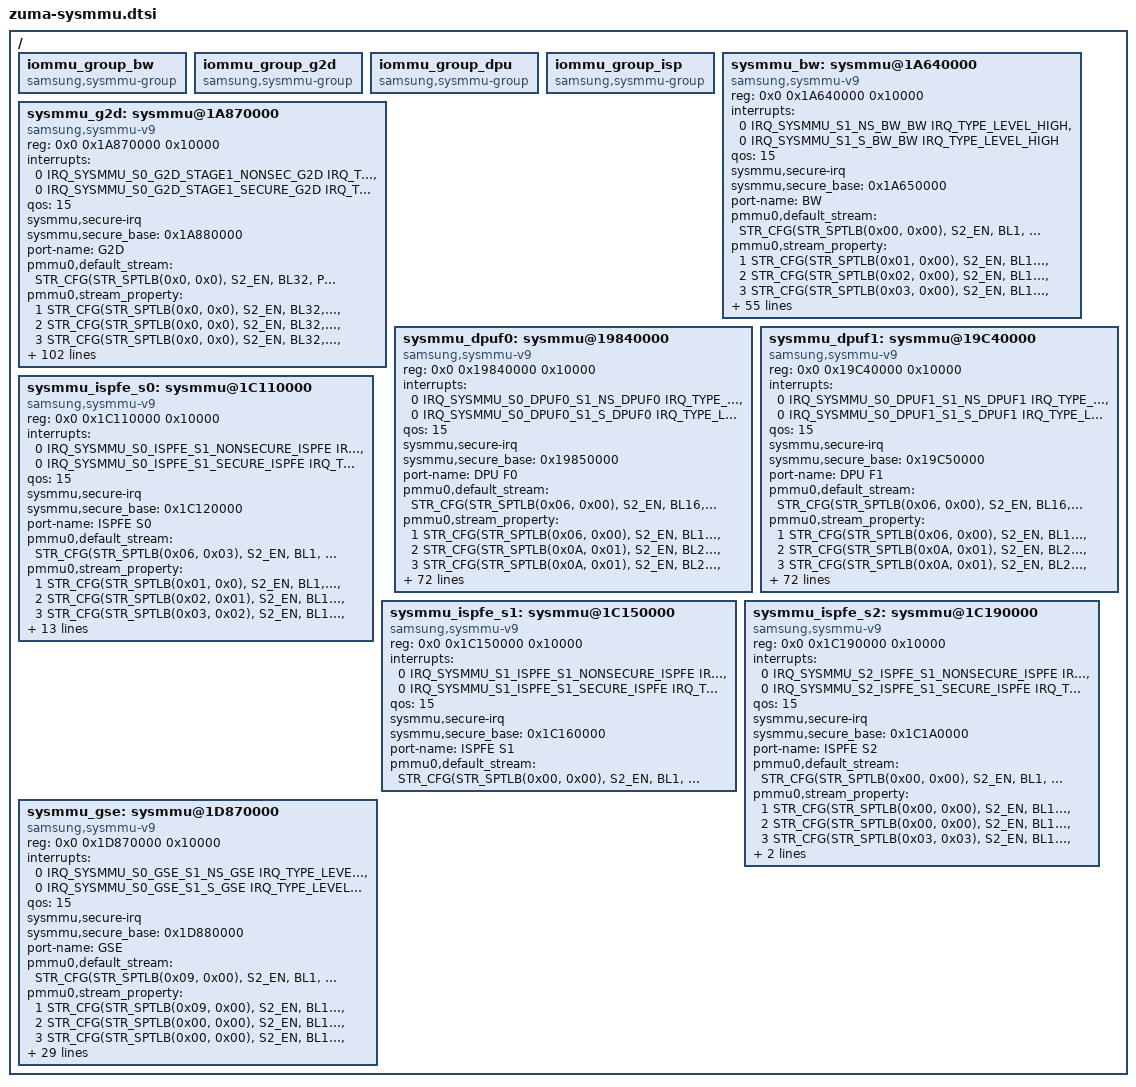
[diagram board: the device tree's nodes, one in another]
// SPDX-License-Identifier: GPL-2.0-only
/*
 * Copyright (c) 2021 Samsung Electronics Co., Ltd.
 *
 */

#include <dt-bindings/interrupt-controller/arm-gic.h>
#include <dt-bindings/interrupt-controller/zuma.h>
#include <dt-bindings/soc/samsung_sysmmu_v9.h>

/ {
	iommu_group_bw: iommu_group_bw {
		compatible = "samsung,sysmmu-group";
	};

	iommu_group_g2d: iommu_group_g2d {
		compatible = "samsung,sysmmu-group";
	};

	iommu_group_dpu: iommu_group_dpu {
		compatible = "samsung,sysmmu-group";
	};

	iommu_group_isp: iommu_group_isp {
		compatible = "samsung,sysmmu-group";
	};

	sysmmu_bw: sysmmu@1A640000 {
		compatible = "samsung,sysmmu-v9";
		reg = <0x0 0x1A640000 0x10000>;

		interrupts = <0 IRQ_SYSMMU_S1_NS_BW_BW IRQ_TYPE_LEVEL_HIGH>,
			     <0 IRQ_SYSMMU_S1_S_BW_BW IRQ_TYPE_LEVEL_HIGH>;

		qos = <15>;

		sysmmu,secure-irq;
		sysmmu,secure_base = <0x1A650000>;
/*		power-domains = <&pd_bw>;
 */
		port-name = "BW";
		#iommu-cells = <0>;
		pmmu0,default_stream = <STR_CFG(STR_SPTLB(0x00, 0x00), S2_EN, BL1, PREF_PRED, STLB_PREF, PTLB_PREF) >;
		pmmu0,stream_property =
			<1 STR_CFG(STR_SPTLB(0x01, 0x00), S2_EN, BL1, PREF_PRED, STLB_PREF, PTLB_PREF) DIR_READ STR_ID(0x02) STR_MASK(0x1F)>,
			<2 STR_CFG(STR_SPTLB(0x02, 0x00), S2_EN, BL1, PREF_PRED, STLB_PREF, PTLB_PREF) DIR_READ STR_ID(0x03) STR_MASK(0x1F)>,
			<3 STR_CFG(STR_SPTLB(0x03, 0x00), S2_EN, BL1, PREF_PRED, STLB_PREF, PTLB_PREF) DIR_READ STR_ID(0x04) STR_MASK(0x1F)>,
			<4 STR_CFG(STR_SPTLB(0x04, 0x00), S2_EN, BL1, PREF_PRED, STLB_PREF, PTLB_PREF) DIR_READ STR_ID(0x05) STR_MASK(0x1F)>,
			<5 STR_CFG(STR_SPTLB(0x00, 0x00), S2_EN, BL1, PREF_PRED, STLB_PREF, PTLB_PREF) DIR_READ STR_ID(0x06) STR_MASK(0x1F)>,
			<6 STR_CFG(STR_SPTLB(0x00, 0x00), S2_EN, BL1, PREF_PRED, STLB_PREF, PTLB_PREF) DIR_READ STR_ID(0x07) STR_MASK(0x1F)>,
			<7 STR_CFG(STR_SPTLB(0x00, 0x00), S2_EN, BL1, PREF_PRED, STLB_PREF, PTLB_PREF) DIR_READ STR_ID(0x08) STR_MASK(0x1F)>,
			<8 STR_CFG(STR_SPTLB(0x00, 0x00), S2_EN, BL1, PREF_PRED, STLB_PREF, PTLB_PREF) DIR_READ STR_ID(0x09) STR_MASK(0x1F)>,
			<9 STR_CFG(STR_SPTLB(0x00, 0x00), S2_EN, BL1, PREF_PRED, STLB_PREF, PTLB_PREF) DIR_READ STR_ID(0x0A) STR_MASK(0x1F)>,
			<10 STR_CFG(STR_SPTLB(0x00, 0x00), S2_EN, BL1, PREF_PRED, STLB_PREF, PTLB_PREF) DIR_READ STR_ID(0x0B) STR_MASK(0x1F)>,
			<11 STR_CFG(STR_SPTLB(0x00, 0x00), S2_EN, BL1, PREF_PRED, STLB_PREF, PTLB_PREF) DIR_READ STR_ID(0x0C) STR_MASK(0x1F)>,
			<12 STR_CFG(STR_SPTLB(0x00, 0x00), S2_EN, BL1, PREF_PRED, STLB_PREF, PTLB_PREF) DIR_READ STR_ID(0x0D) STR_MASK(0x1F)>,
			<13 STR_CFG(STR_SPTLB(0x00, 0x00), S2_EN, BL1, PREF_PRED, STLB_PREF, PTLB_PREF) DIR_READ STR_ID(0x0E) STR_MASK(0x1F)>,
			<14 STR_CFG(STR_SPTLB(0x00, 0x00), S2_EN, BL1, PREF_PRED, STLB_PREF, PTLB_PREF) DIR_READ STR_ID(0x0F) STR_MASK(0x1F)>,
			<15 STR_CFG(STR_SPTLB(0x00, 0x00), S2_EN, BL1, PREF_PRED, STLB_PREF, PTLB_PREF) DIR_READ STR_ID(0x10) STR_MASK(0x1F)>,
			<16 STR_CFG(STR_SPTLB(0x00, 0x00), S2_EN, BL1, PREF_PRED, STLB_PREF, PTLB_PREF) DIR_READ STR_ID(0x11) STR_MASK(0x1F)>,
			<17 STR_CFG(STR_SPTLB(0x00, 0x00), S2_EN, BL1, PREF_PRED, STLB_NONE, PTLB_NONE) DIR_READ STR_ID(0x12) STR_MASK(0x1F)>,
			<18 STR_CFG(STR_SPTLB(0x00, 0x00), S2_EN, BL1, PREF_PRED, STLB_PREF, PTLB_PREF) DIR_READ STR_ID(0x13) STR_MASK(0x1F)>,
			<19 STR_CFG(STR_SPTLB(0x00, 0x00), S2_EN, BL1, PREF_PRED, STLB_PREF, PTLB_PREF) DIR_READ STR_ID(0x14) STR_MASK(0x1F)>,
			<20 STR_CFG(STR_SPTLB(0x00, 0x00), S2_EN, BL1, PREF_PRED, STLB_PREF, PTLB_PREF) DIR_READ STR_ID(0x15) STR_MASK(0x1F)>,
			<21 STR_CFG(STR_SPTLB(0x00, 0x00), S2_EN, BL1, PREF_PRED, STLB_PREF, PTLB_PREF) DIR_READ STR_ID(0x16) STR_MASK(0x1F)>,
			<22 STR_CFG(STR_SPTLB(0x00, 0x00), S2_EN, BL1, PREF_PRED, STLB_NONE, PTLB_NONE) DIR_READ STR_ID(0x17) STR_MASK(0x1F)>,
			<23 STR_CFG(STR_SPTLB(0x00, 0x00), S2_EN, BL1, PREF_PRED, STLB_PREF, PTLB_PREF) DIR_READ STR_ID(0x18) STR_MASK(0x1F)>,
			<24 STR_CFG(STR_SPTLB(0x00, 0x00), S2_EN, BL1, PREF_PRED, STLB_PREF, PTLB_PREF) DIR_READ STR_ID(0x19) STR_MASK(0x1F)>,
			<25 STR_CFG(STR_SPTLB(0x00, 0x00), S2_EN, BL1, PREF_PRED, STLB_PREF, PTLB_PREF) DIR_READ STR_ID(0x1A) STR_MASK(0x1F)>,
			<26 STR_CFG(STR_SPTLB(0x00, 0x00), S2_EN, BL1, PREF_PRED, STLB_PREF, PTLB_PREF) DIR_READ STR_ID(0x1B) STR_MASK(0x1F)>,
			<27 STR_CFG(STR_SPTLB(0x00, 0x00), S2_EN, BL1, PREF_PRED, STLB_NONE, PTLB_NONE) DIR_READ STR_ID(0x1C) STR_MASK(0x1F)>,
			<28 STR_CFG(STR_SPTLB(0x00, 0x00), S2_EN, BL1, PREF_PRED, STLB_PREF, PTLB_PREF) DIR_READ STR_ID(0x1D) STR_MASK(0x1F)>,
			<29 STR_CFG(STR_SPTLB(0x00, 0x00), S2_EN, BL1, PREF_PRED, STLB_PREF, PTLB_PREF) DIR_READ STR_ID(0x1E) STR_MASK(0x1F)>,
			<30 STR_CFG(STR_SPTLB(0x00, 0x00), S2_EN, BL1, PREF_PRED, STLB_PREF, PTLB_PREF) DIR_READ STR_ID(0x1F) STR_MASK(0x1F)>,
			<31 STR_CFG(STR_SPTLB(0x00, 0x00), S2_EN, BL1, PREF_PRED, STLB_PREF, PTLB_PREF) DIR_WRITE STR_ID(0x01) STR_MASK(0x3F)>,
			<32 STR_CFG(STR_SPTLB(0x00, 0x00), S2_EN, BL1, PREF_PRED, STLB_NONE, PTLB_NONE) DIR_WRITE STR_ID(0x02) STR_MASK(0x3F)>,
			<33 STR_CFG(STR_SPTLB(0x00, 0x00), S2_EN, BL1, PREF_PRED, STLB_PREF, PTLB_PREF) DIR_WRITE STR_ID(0x03) STR_MASK(0x3F)>,
			<34 STR_CFG(STR_SPTLB(0x00, 0x00), S2_EN, BL1, PREF_PRED, STLB_PREF, PTLB_PREF) DIR_WRITE STR_ID(0x04) STR_MASK(0x3F)>,
			<35 STR_CFG(STR_SPTLB(0x00, 0x00), S2_EN, BL1, PREF_PRED, STLB_PREF, PTLB_PREF) DIR_WRITE STR_ID(0x05) STR_MASK(0x3F)>,
			<36 STR_CFG(STR_SPTLB(0x00, 0x00), S2_EN, BL1, PREF_PRED, STLB_PREF, PTLB_PREF) DIR_WRITE STR_ID(0x06) STR_MASK(0x3F)>,
			<37 STR_CFG(STR_SPTLB(0x00, 0x00), S2_EN, BL1, PREF_PRED, STLB_PREF, PTLB_PREF) DIR_WRITE STR_ID(0x07) STR_MASK(0x3F)>,
			<38 STR_CFG(STR_SPTLB(0x00, 0x00), S2_EN, BL1, PREF_PRED, STLB_PREF, PTLB_PREF) DIR_WRITE STR_ID(0x08) STR_MASK(0x3F)>,
			<39 STR_CFG(STR_SPTLB(0x00, 0x00), S2_EN, BL1, PREF_PRED, STLB_PREF, PTLB_PREF) DIR_WRITE STR_ID(0x09) STR_MASK(0x3F)>,
			<40 STR_CFG(STR_SPTLB(0x00, 0x00), S2_EN, BL1, PREF_PRED, STLB_PREF, PTLB_PREF) DIR_WRITE STR_ID(0x0A) STR_MASK(0x3F)>,
			<41 STR_CFG(STR_SPTLB(0x00, 0x00), S2_EN, BL1, PREF_PRED, STLB_PREF, PTLB_PREF) DIR_WRITE STR_ID(0x0B) STR_MASK(0x3F)>,
			<42 STR_CFG(STR_SPTLB(0x00, 0x00), S2_EN, BL1, PREF_PRED, STLB_PREF, PTLB_PREF) DIR_WRITE STR_ID(0x0C) STR_MASK(0x3F)>,
			<43 STR_CFG(STR_SPTLB(0x00, 0x00), S2_EN, BL1, PREF_PRED, STLB_PREF, PTLB_PREF) DIR_WRITE STR_ID(0x0D) STR_MASK(0x3F)>,
			<44 STR_CFG(STR_SPTLB(0x00, 0x00), S2_EN, BL1, PREF_PRED, STLB_PREF, PTLB_PREF) DIR_WRITE STR_ID(0x0E) STR_MASK(0x3F)>,
			<45 STR_CFG(STR_SPTLB(0x00, 0x00), S2_EN, BL1, PREF_PRED, STLB_PREF, PTLB_PREF) DIR_WRITE STR_ID(0x0F) STR_MASK(0x3F)>,
			<46 STR_CFG(STR_SPTLB(0x00, 0x00), S2_EN, BL1, PREF_PRED, STLB_PREF, PTLB_PREF) DIR_WRITE STR_ID(0x10) STR_MASK(0x3F)>,
			<47 STR_CFG(STR_SPTLB(0x00, 0x00), S2_EN, BL1, PREF_PRED, STLB_PREF, PTLB_PREF) DIR_WRITE STR_ID(0x11) STR_MASK(0x3F)>,
			<48 STR_CFG(STR_SPTLB(0x00, 0x00), S2_EN, BL1, PREF_PRED, STLB_PREF, PTLB_PREF) DIR_WRITE STR_ID(0x12) STR_MASK(0x3F)>,
			<49 STR_CFG(STR_SPTLB(0x00, 0x00), S2_EN, BL1, PREF_PRED, STLB_NONE, PTLB_NONE) DIR_WRITE STR_ID(0x13) STR_MASK(0x3F)>,
			<50 STR_CFG(STR_SPTLB(0x00, 0x00), S2_EN, BL1, PREF_PRED, STLB_NONE, PTLB_NONE) DIR_WRITE STR_ID(0x14) STR_MASK(0x3F)>,
			<51 STR_CFG(STR_SPTLB(0x00, 0x00), S2_EN, BL8, PREF_PRED, STLB_PREF, PTLB_PREF) DIR_WRITE STR_ID(0x15) STR_MASK(0x3F)>,
			<52 STR_CFG(STR_SPTLB(0x00, 0x00), S2_EN, BL1, PREF_PRED, STLB_NONE, PTLB_NONE) DIR_WRITE STR_ID(0x16) STR_MASK(0x3F)>,
			<53 STR_CFG(STR_SPTLB(0x00, 0x00), S2_EN, BL8, PREF_PRED, STLB_PREF, PTLB_PREF) DIR_WRITE STR_ID(0x17) STR_MASK(0x3F)>,
			<54 STR_CFG(STR_SPTLB(0x00, 0x00), S2_EN, BL1, PREF_PRED, STLB_NONE, PTLB_NONE) DIR_WRITE STR_ID(0x18) STR_MASK(0x3F)>,
			<55 STR_CFG(STR_SPTLB(0x00, 0x00), S2_EN, BL8, PREF_PRED, STLB_PREF, PTLB_PREF) DIR_WRITE STR_ID(0x19) STR_MASK(0x3F)>,
			<56 STR_CFG(STR_SPTLB(0x00, 0x00), S2_EN, BL1, PREF_PRED, STLB_NONE, PTLB_NONE) DIR_WRITE STR_ID(0x1A) STR_MASK(0x3F)>,
			<57 STR_CFG(STR_SPTLB(0x00, 0x00), S2_EN, BL8, PREF_PRED, STLB_PREF, PTLB_PREF) DIR_WRITE STR_ID(0x1B) STR_MASK(0x3F)>,
			<58 STR_CFG(STR_SPTLB(0x00, 0x00), S2_EN, BL1, PREF_PRED, STLB_NONE, PTLB_NONE) DIR_WRITE STR_ID(0x1C) STR_MASK(0x3F)>;
	};

	sysmmu_g2d: sysmmu@1A870000 {
		compatible = "samsung,sysmmu-v9";
		reg = <0x0 0x1A870000 0x10000>;

		interrupts = <0 IRQ_SYSMMU_S0_G2D_STAGE1_NONSEC_G2D IRQ_TYPE_LEVEL_HIGH>,
			     <0 IRQ_SYSMMU_S0_G2D_STAGE1_SECURE_G2D IRQ_TYPE_LEVEL_HIGH>;

		qos = <15>;

		sysmmu,secure-irq;
		sysmmu,secure_base = <0x1A880000>;
/*		power-domains = <&pd_g2d>;
 */
		port-name = "G2D";
		#iommu-cells = <0>;

		pmmu0,default_stream = <STR_CFG(STR_SPTLB(0x0, 0x0), S2_EN, BL32, PREF_PRED, STLB_NONE, PTLB_NONE)>;
		pmmu0,stream_property =
			<1 STR_CFG(STR_SPTLB(0x0, 0x0), S2_EN, BL32, PREF_PRED, STLB_NONE, PTLB_NONE) DIR_RW STR_ID(0x01) STR_MASK(0x7F)>,
			<2 STR_CFG(STR_SPTLB(0x0, 0x0), S2_EN, BL32, PREF_PRED, STLB_NONE, PTLB_NONE) DIR_RW STR_ID(0x02) STR_MASK(0x7F)>,
			<3 STR_CFG(STR_SPTLB(0x0, 0x0), S2_EN, BL32, PREF_PRED, STLB_NONE, PTLB_NONE) DIR_RW STR_ID(0x03) STR_MASK(0x7F)>,
			<4 STR_CFG(STR_SPTLB(0x0, 0x0), S2_EN, BL32, PREF_PRED, STLB_NONE, PTLB_NONE) DIR_RW STR_ID(0x04) STR_MASK(0x7F)>,
			<5 STR_CFG(STR_SPTLB(0x0, 0x0), S2_EN, BL32, PREF_PRED, STLB_NONE, PTLB_NONE) DIR_RW STR_ID(0x09) STR_MASK(0x7F)>,
			<6 STR_CFG(STR_SPTLB(0x0, 0x0), S2_EN, BL32, PREF_PRED, STLB_NONE, PTLB_NONE) DIR_RW STR_ID(0x0A) STR_MASK(0x7F)>,
			<7 STR_CFG(STR_SPTLB(0x0, 0x0), S2_EN, BL32, PREF_PRED, STLB_NONE, PTLB_NONE) DIR_RW STR_ID(0x0B) STR_MASK(0x7F)>,
			<8 STR_CFG(STR_SPTLB(0x0, 0x0), S2_EN, BL32, PREF_PRED, STLB_NONE, PTLB_NONE) DIR_RW STR_ID(0x0C) STR_MASK(0x7F)>,
			<9 STR_CFG(STR_SPTLB(0x0, 0x0), S2_EN, BL32, PREF_PRED, STLB_NONE, PTLB_NONE) DIR_RW STR_ID(0x11) STR_MASK(0x7F)>,
			<10 STR_CFG(STR_SPTLB(0x0, 0x0), S2_EN, BL32, PREF_PRED, STLB_NONE, PTLB_NONE) DIR_RW STR_ID(0x12) STR_MASK(0x7F)>,
			<11 STR_CFG(STR_SPTLB(0x0, 0x0), S2_EN, BL32, PREF_PRED, STLB_NONE, PTLB_NONE) DIR_RW STR_ID(0x13) STR_MASK(0x7F)>,
			<12 STR_CFG(STR_SPTLB(0x0, 0x0), S2_EN, BL32, PREF_PRED, STLB_NONE, PTLB_NONE) DIR_RW STR_ID(0x14) STR_MASK(0x7F)>,
			<13 STR_CFG(STR_SPTLB(0x0, 0x0), S2_EN, BL32, PREF_PRED, STLB_NONE, PTLB_NONE) DIR_RW STR_ID(0x21) STR_MASK(0x7F)>,
			<14 STR_CFG(STR_SPTLB(0x0, 0x0), S2_EN, BL32, PREF_PRED, STLB_NONE, PTLB_NONE) DIR_RW STR_ID(0x22) STR_MASK(0x7F)>,
			<15 STR_CFG(STR_SPTLB(0x0, 0x0), S2_EN, BL32, PREF_PRED, STLB_NONE, PTLB_NONE) DIR_RW STR_ID(0x23) STR_MASK(0x7F)>,
			<16 STR_CFG(STR_SPTLB(0x0, 0x0), S2_EN, BL32, PREF_PRED, STLB_NONE, PTLB_NONE) DIR_RW STR_ID(0x24) STR_MASK(0x7F)>,
			<17 STR_CFG(STR_SPTLB(0x0, 0x0), S2_EN, BL32, PREF_PRED, STLB_NONE, PTLB_NONE) DIR_RW STR_ID(0x29) STR_MASK(0x7F)>,
			<18 STR_CFG(STR_SPTLB(0x0, 0x0), S2_EN, BL32, PREF_PRED, STLB_NONE, PTLB_NONE) DIR_RW STR_ID(0x2A) STR_MASK(0x7F)>,
			<19 STR_CFG(STR_SPTLB(0x0, 0x0), S2_EN, BL32, PREF_PRED, STLB_NONE, PTLB_NONE) DIR_RW STR_ID(0x2B) STR_MASK(0x7F)>,
			<20 STR_CFG(STR_SPTLB(0x0, 0x0), S2_EN, BL32, PREF_PRED, STLB_NONE, PTLB_NONE) DIR_RW STR_ID(0x2C) STR_MASK(0x7F)>,
			<21 STR_CFG(STR_SPTLB(0x0, 0x0), S2_EN, BL32, PREF_PRED, STLB_NONE, PTLB_NONE) DIR_RW STR_ID(0x40) STR_MASK(0x7F)>,
			<22 STR_CFG(STR_SPTLB(0x0, 0x0), S2_EN, BL32, PREF_PRED, STLB_NONE, PTLB_NONE) DIR_RW STR_ID(0x41) STR_MASK(0x7F)>,
			<23 STR_CFG(STR_SPTLB(0x0, 0x0), S2_EN, BL32, PREF_PRED, STLB_NONE, PTLB_NONE) DIR_RW STR_ID(0x42) STR_MASK(0x7F)>,
			<24 STR_CFG(STR_SPTLB(0x0, 0x0), S2_EN, BL32, PREF_PRED, STLB_NONE, PTLB_NONE) DIR_RW STR_ID(0x43) STR_MASK(0x7F)>,
			<25 STR_CFG(STR_SPTLB(0x0, 0x0), S2_EN, BL32, PREF_PRED, STLB_NONE, PTLB_NONE) DIR_RW STR_ID(0x44) STR_MASK(0x7F)>,
			<26 STR_CFG(STR_SPTLB(0x0, 0x0), S2_EN, BL32, PREF_PRED, STLB_NONE, PTLB_NONE) DIR_RW STR_ID(0x49) STR_MASK(0x7F)>,
			<27 STR_CFG(STR_SPTLB(0x0, 0x0), S2_EN, BL32, PREF_PRED, STLB_NONE, PTLB_NONE) DIR_RW STR_ID(0x4A) STR_MASK(0x7F)>,
			<28 STR_CFG(STR_SPTLB(0x0, 0x0), S2_EN, BL32, PREF_PRED, STLB_NONE, PTLB_NONE) DIR_RW STR_ID(0x4B) STR_MASK(0x7F)>,
			<29 STR_CFG(STR_SPTLB(0x0, 0x0), S2_EN, BL32, PREF_PRED, STLB_NONE, PTLB_NONE) DIR_RW STR_ID(0x4C) STR_MASK(0x7F)>,
			<30 STR_CFG(STR_SPTLB(0x0, 0x0), S2_EN, BL32, PREF_PRED, STLB_NONE, PTLB_NONE) DIR_RW STR_ID(0x51) STR_MASK(0x7F)>,
			<31 STR_CFG(STR_SPTLB(0x0, 0x0), S2_EN, BL32, PREF_PRED, STLB_NONE, PTLB_NONE) DIR_RW STR_ID(0x52) STR_MASK(0x7F)>,
			<32 STR_CFG(STR_SPTLB(0x0, 0x0), S2_EN, BL32, PREF_PRED, STLB_NONE, PTLB_NONE) DIR_RW STR_ID(0x53) STR_MASK(0x7F)>,
			<33 STR_CFG(STR_SPTLB(0x0, 0x0), S2_EN, BL32, PREF_PRED, STLB_NONE, PTLB_NONE) DIR_RW STR_ID(0x54) STR_MASK(0x7F)>,
			<34 STR_CFG(STR_SPTLB(0x0, 0x0), S2_EN, BL32, PREF_PRED, STLB_NONE, PTLB_NONE) DIR_RW STR_ID(0x61) STR_MASK(0x7F)>,
			<35 STR_CFG(STR_SPTLB(0x0, 0x0), S2_EN, BL32, PREF_PRED, STLB_NONE, PTLB_NONE) DIR_RW STR_ID(0x62) STR_MASK(0x7F)>,
			<36 STR_CFG(STR_SPTLB(0x0, 0x0), S2_EN, BL32, PREF_PRED, STLB_NONE, PTLB_NONE) DIR_RW STR_ID(0x63) STR_MASK(0x7F)>,
			<37 STR_CFG(STR_SPTLB(0x0, 0x0), S2_EN, BL32, PREF_PRED, STLB_NONE, PTLB_NONE) DIR_RW STR_ID(0x64) STR_MASK(0x7F)>,
			<38 STR_CFG(STR_SPTLB(0x0, 0x0), S2_EN, BL32, PREF_PRED, STLB_NONE, PTLB_NONE) DIR_RW STR_ID(0x69) STR_MASK(0x7F)>,
			<39 STR_CFG(STR_SPTLB(0x0, 0x0), S2_EN, BL32, PREF_PRED, STLB_NONE, PTLB_NONE) DIR_RW STR_ID(0x6A) STR_MASK(0x7F)>,
			<40 STR_CFG(STR_SPTLB(0x0, 0x0), S2_EN, BL32, PREF_PRED, STLB_NONE, PTLB_NONE) DIR_RW STR_ID(0x6B) STR_MASK(0x7F)>,
			<41 STR_CFG(STR_SPTLB(0x0, 0x0), S2_EN, BL32, PREF_PRED, STLB_NONE, PTLB_NONE) DIR_RW STR_ID(0x6C) STR_MASK(0x7F)>,
			<42 STR_CFG(STR_SPTLB(0x0, 0x0), S2_EN, BL32, PREF_PRED, STLB_NONE, PTLB_NONE) DIR_RW STR_ID(0x00) STR_MASK(0x3F)>,
			<43 STR_CFG(STR_SPTLB(0x0, 0x0), S2_EN, BL32, PREF_PRED, STLB_NONE, PTLB_NONE) DIR_RW STR_ID(0x04) STR_MASK(0x3F)>,
			<44 STR_CFG(STR_SPTLB(0x0, 0x0), S2_EN, BL32, PREF_PRED, STLB_NONE, PTLB_NONE) DIR_RW STR_ID(0x08) STR_MASK(0x3F)>,
			<45 STR_CFG(STR_SPTLB(0x0, 0x0), S2_EN, BL32, PREF_PRED, STLB_NONE, PTLB_NONE) DIR_RW STR_ID(0x10) STR_MASK(0x3F)>,
			<46 STR_CFG(STR_SPTLB(0x0, 0x0), S2_EN, BL32, PREF_PRED, STLB_NONE, PTLB_NONE) DIR_RW STR_ID(0x14) STR_MASK(0x3F)>,
			<47 STR_CFG(STR_SPTLB(0x0, 0x0), S2_EN, BL32, PREF_PRED, STLB_NONE, PTLB_NONE) DIR_RW STR_ID(0x20) STR_MASK(0x3F)>,
			<48 STR_CFG(STR_SPTLB(0x0, 0x0), S2_EN, BL32, PREF_PRED, STLB_NONE, PTLB_NONE) DIR_RW STR_ID(0x24) STR_MASK(0x3F)>,
			<49 STR_CFG(STR_SPTLB(0x0, 0x0), S2_EN, BL32, PREF_PRED, STLB_NONE, PTLB_NONE) DIR_RW STR_ID(0x28) STR_MASK(0x3F)>,
			<50 STR_CFG(STR_SPTLB(0x0, 0x0), S2_EN, BL32, PREF_PRED, STLB_NONE, PTLB_NONE) DIR_RW STR_ID(0x30) STR_MASK(0x3F)>,
			<51 STR_CFG(STR_SPTLB(0x0, 0x0), S2_EN, BL32, PREF_PRED, STLB_NONE, PTLB_NONE) DIR_RW STR_ID(0x34) STR_MASK(0x3F)>;

		pmmu1,default_stream = <STR_CFG(STR_SPTLB(0x0, 0x0), S2_EN, BL32, PREF_PRED, STLB_NONE, PTLB_NONE)>;
		pmmu1,stream_property =
			<1 STR_CFG(STR_SPTLB(0x0, 0x0), S2_EN, BL32, PREF_PRED, STLB_NONE, PTLB_NONE) DIR_RW STR_ID(0x02) STR_MASK(0x7F)>,
			<2 STR_CFG(STR_SPTLB(0x0, 0x0), S2_EN, BL32, PREF_PRED, STLB_NONE, PTLB_NONE) DIR_RW STR_ID(0x03) STR_MASK(0x7F)>,
			<3 STR_CFG(STR_SPTLB(0x0, 0x0), S2_EN, BL32, PREF_PRED, STLB_NONE, PTLB_NONE) DIR_RW STR_ID(0x04) STR_MASK(0x7F)>,
			<4 STR_CFG(STR_SPTLB(0x0, 0x0), S2_EN, BL32, PREF_PRED, STLB_NONE, PTLB_NONE) DIR_RW STR_ID(0x09) STR_MASK(0x7F)>,
			<5 STR_CFG(STR_SPTLB(0x0, 0x0), S2_EN, BL32, PREF_PRED, STLB_NONE, PTLB_NONE) DIR_RW STR_ID(0x0A) STR_MASK(0x7F)>,
			<6 STR_CFG(STR_SPTLB(0x0, 0x0), S2_EN, BL32, PREF_PRED, STLB_NONE, PTLB_NONE) DIR_RW STR_ID(0x0B) STR_MASK(0x7F)>,
			<7 STR_CFG(STR_SPTLB(0x0, 0x0), S2_EN, BL32, PREF_PRED, STLB_NONE, PTLB_NONE) DIR_RW STR_ID(0x0C) STR_MASK(0x7F)>,
			<8 STR_CFG(STR_SPTLB(0x0, 0x0), S2_EN, BL32, PREF_PRED, STLB_NONE, PTLB_NONE) DIR_RW STR_ID(0x11) STR_MASK(0x7F)>,
			<9 STR_CFG(STR_SPTLB(0x0, 0x0), S2_EN, BL32, PREF_PRED, STLB_NONE, PTLB_NONE) DIR_RW STR_ID(0x12) STR_MASK(0x7F)>,
			<10 STR_CFG(STR_SPTLB(0x0, 0x0), S2_EN, BL32, PREF_PRED, STLB_NONE, PTLB_NONE) DIR_RW STR_ID(0x13) STR_MASK(0x7F)>,
			<11 STR_CFG(STR_SPTLB(0x0, 0x0), S2_EN, BL32, PREF_PRED, STLB_NONE, PTLB_NONE) DIR_RW STR_ID(0x14) STR_MASK(0x7F)>,
			<12 STR_CFG(STR_SPTLB(0x0, 0x0), S2_EN, BL32, PREF_PRED, STLB_NONE, PTLB_NONE) DIR_RW STR_ID(0x21) STR_MASK(0x7F)>,
			<13 STR_CFG(STR_SPTLB(0x0, 0x0), S2_EN, BL32, PREF_PRED, STLB_NONE, PTLB_NONE) DIR_RW STR_ID(0x22) STR_MASK(0x7F)>,
			<14 STR_CFG(STR_SPTLB(0x0, 0x0), S2_EN, BL32, PREF_PRED, STLB_NONE, PTLB_NONE) DIR_RW STR_ID(0x23) STR_MASK(0x7F)>,
			<15 STR_CFG(STR_SPTLB(0x0, 0x0), S2_EN, BL32, PREF_PRED, STLB_NONE, PTLB_NONE) DIR_RW STR_ID(0x24) STR_MASK(0x7F)>,
			<16 STR_CFG(STR_SPTLB(0x0, 0x0), S2_EN, BL32, PREF_PRED, STLB_NONE, PTLB_NONE) DIR_RW STR_ID(0x29) STR_MASK(0x7F)>,
			<17 STR_CFG(STR_SPTLB(0x0, 0x0), S2_EN, BL32, PREF_PRED, STLB_NONE, PTLB_NONE) DIR_RW STR_ID(0x2A) STR_MASK(0x7F)>,
			<18 STR_CFG(STR_SPTLB(0x0, 0x0), S2_EN, BL32, PREF_PRED, STLB_NONE, PTLB_NONE) DIR_RW STR_ID(0x2B) STR_MASK(0x7F)>,
			<19 STR_CFG(STR_SPTLB(0x0, 0x0), S2_EN, BL32, PREF_PRED, STLB_NONE, PTLB_NONE) DIR_RW STR_ID(0x2C) STR_MASK(0x7F)>,
			<20 STR_CFG(STR_SPTLB(0x0, 0x0), S2_EN, BL32, PREF_PRED, STLB_NONE, PTLB_NONE) DIR_RW STR_ID(0x41) STR_MASK(0x7F)>,
			<21 STR_CFG(STR_SPTLB(0x0, 0x0), S2_EN, BL32, PREF_PRED, STLB_NONE, PTLB_NONE) DIR_RW STR_ID(0x42) STR_MASK(0x7F)>,
			<22 STR_CFG(STR_SPTLB(0x0, 0x0), S2_EN, BL32, PREF_PRED, STLB_NONE, PTLB_NONE) DIR_RW STR_ID(0x43) STR_MASK(0x7F)>,
			<23 STR_CFG(STR_SPTLB(0x0, 0x0), S2_EN, BL32, PREF_PRED, STLB_NONE, PTLB_NONE) DIR_RW STR_ID(0x44) STR_MASK(0x7F)>,
			<24 STR_CFG(STR_SPTLB(0x0, 0x0), S2_EN, BL32, PREF_PRED, STLB_NONE, PTLB_NONE) DIR_RW STR_ID(0x49) STR_MASK(0x7F)>,
			<25 STR_CFG(STR_SPTLB(0x0, 0x0), S2_EN, BL32, PREF_PRED, STLB_NONE, PTLB_NONE) DIR_RW STR_ID(0x4A) STR_MASK(0x7F)>,
			<26 STR_CFG(STR_SPTLB(0x0, 0x0), S2_EN, BL32, PREF_PRED, STLB_NONE, PTLB_NONE) DIR_RW STR_ID(0x4B) STR_MASK(0x7F)>,
			<27 STR_CFG(STR_SPTLB(0x0, 0x0), S2_EN, BL32, PREF_PRED, STLB_NONE, PTLB_NONE) DIR_RW STR_ID(0x4C) STR_MASK(0x7F)>,
			<28 STR_CFG(STR_SPTLB(0x0, 0x0), S2_EN, BL32, PREF_PRED, STLB_NONE, PTLB_NONE) DIR_RW STR_ID(0x51) STR_MASK(0x7F)>,
			<29 STR_CFG(STR_SPTLB(0x0, 0x0), S2_EN, BL32, PREF_PRED, STLB_NONE, PTLB_NONE) DIR_RW STR_ID(0x52) STR_MASK(0x7F)>,
			<30 STR_CFG(STR_SPTLB(0x0, 0x0), S2_EN, BL32, PREF_PRED, STLB_NONE, PTLB_NONE) DIR_RW STR_ID(0x53) STR_MASK(0x7F)>,
			<31 STR_CFG(STR_SPTLB(0x0, 0x0), S2_EN, BL32, PREF_PRED, STLB_NONE, PTLB_NONE) DIR_RW STR_ID(0x54) STR_MASK(0x7F)>,
			<32 STR_CFG(STR_SPTLB(0x0, 0x0), S2_EN, BL32, PREF_PRED, STLB_NONE, PTLB_NONE) DIR_RW STR_ID(0x61) STR_MASK(0x7F)>,
			<33 STR_CFG(STR_SPTLB(0x0, 0x0), S2_EN, BL32, PREF_PRED, STLB_NONE, PTLB_NONE) DIR_RW STR_ID(0x62) STR_MASK(0x7F)>,
			<34 STR_CFG(STR_SPTLB(0x0, 0x0), S2_EN, BL32, PREF_PRED, STLB_NONE, PTLB_NONE) DIR_RW STR_ID(0x63) STR_MASK(0x7F)>,
			<35 STR_CFG(STR_SPTLB(0x0, 0x0), S2_EN, BL32, PREF_PRED, STLB_NONE, PTLB_NONE) DIR_RW STR_ID(0x64) STR_MASK(0x7F)>,
			<36 STR_CFG(STR_SPTLB(0x0, 0x0), S2_EN, BL32, PREF_PRED, STLB_NONE, PTLB_NONE) DIR_RW STR_ID(0x69) STR_MASK(0x7F)>,
			<37 STR_CFG(STR_SPTLB(0x0, 0x0), S2_EN, BL32, PREF_PRED, STLB_NONE, PTLB_NONE) DIR_RW STR_ID(0x6A) STR_MASK(0x7F)>,
			<38 STR_CFG(STR_SPTLB(0x0, 0x0), S2_EN, BL32, PREF_PRED, STLB_NONE, PTLB_NONE) DIR_RW STR_ID(0x6B) STR_MASK(0x7F)>,
			<39 STR_CFG(STR_SPTLB(0x0, 0x0), S2_EN, BL32, PREF_PRED, STLB_NONE, PTLB_NONE) DIR_RW STR_ID(0x6C) STR_MASK(0x7F)>,
			<40 STR_CFG(STR_SPTLB(0x0, 0x0), S2_EN, BL32, PREF_PRED, STLB_NONE, PTLB_NONE) DIR_RW STR_ID(0x00) STR_MASK(0x3F)>,
			<41 STR_CFG(STR_SPTLB(0x0, 0x0), S2_EN, BL32, PREF_PRED, STLB_NONE, PTLB_NONE) DIR_RW STR_ID(0x04) STR_MASK(0x3F)>,
			<42 STR_CFG(STR_SPTLB(0x0, 0x0), S2_EN, BL32, PREF_PRED, STLB_NONE, PTLB_NONE) DIR_RW STR_ID(0x08) STR_MASK(0x3F)>,
			<43 STR_CFG(STR_SPTLB(0x0, 0x0), S2_EN, BL32, PREF_PRED, STLB_NONE, PTLB_NONE) DIR_RW STR_ID(0x10) STR_MASK(0x3F)>,
			<44 STR_CFG(STR_SPTLB(0x0, 0x0), S2_EN, BL32, PREF_PRED, STLB_NONE, PTLB_NONE) DIR_RW STR_ID(0x14) STR_MASK(0x3F)>,
			<45 STR_CFG(STR_SPTLB(0x0, 0x0), S2_EN, BL32, PREF_PRED, STLB_NONE, PTLB_NONE) DIR_RW STR_ID(0x20) STR_MASK(0x3F)>,
			<46 STR_CFG(STR_SPTLB(0x0, 0x0), S2_EN, BL32, PREF_PRED, STLB_NONE, PTLB_NONE) DIR_RW STR_ID(0x24) STR_MASK(0x3F)>,
			<47 STR_CFG(STR_SPTLB(0x0, 0x0), S2_EN, BL32, PREF_PRED, STLB_NONE, PTLB_NONE) DIR_RW STR_ID(0x28) STR_MASK(0x3F)>,
			<48 STR_CFG(STR_SPTLB(0x0, 0x0), S2_EN, BL32, PREF_PRED, STLB_NONE, PTLB_NONE) DIR_RW STR_ID(0x30) STR_MASK(0x3F)>,
			<49 STR_CFG(STR_SPTLB(0x0, 0x0), S2_EN, BL32, PREF_PRED, STLB_NONE, PTLB_NONE) DIR_RW STR_ID(0x34) STR_MASK(0x3F)>;

		pmmu2,default_stream = <STR_CFG(STR_SPTLB(0x0, 0x0), S2_EN, BL8, PREF_PRED, STLB_NONE, PTLB_NONE)>;
	};

	sysmmu_dpuf0: sysmmu@19840000 {
		compatible = "samsung,sysmmu-v9";
		reg = <0x0 0x19840000 0x10000>;

		interrupts = <0 IRQ_SYSMMU_S0_DPUF0_S1_NS_DPUF0 IRQ_TYPE_LEVEL_HIGH>,
			     <0 IRQ_SYSMMU_S0_DPUF0_S1_S_DPUF0 IRQ_TYPE_LEVEL_HIGH>;

		qos = <15>;

		sysmmu,secure-irq;
		sysmmu,secure_base = <0x19850000>;
/*              power-domains = <&pd_dpu>;
 */
		port-name = "DPU F0";
		#iommu-cells = <0>;
		pmmu0,default_stream = <STR_CFG(STR_SPTLB(0x06, 0x00), S2_EN, BL16, PREF_PRED, STLB_PREF, PTLB_NONE)>;
		pmmu0,stream_property =
			<1 STR_CFG(STR_SPTLB(0x06, 0x00), S2_EN, BL16, PREF_PRED, STLB_PREF, PTLB_NONE)	DIR_READ STR_ID(0x40) STR_MASK(0x7F)>,
			<2 STR_CFG(STR_SPTLB(0x0A, 0x01), S2_EN, BL2, PREF_PRED, STLB_PREF, PTLB_PREF)	DIR_READ STR_ID(0x01) STR_MASK(0x7F)>,
			<3 STR_CFG(STR_SPTLB(0x0A, 0x01), S2_EN, BL2, PREF_PRED, STLB_PREF, PTLB_PREF)	DIR_READ STR_ID(0x41) STR_MASK(0x7F)>,
			<4 STR_CFG(STR_SPTLB(0x00, 0x02), S2_EN, BL32, PREF_PRED, STLB_PREF, PTLB_NONE)	DIR_READ STR_ID(0x08) STR_MASK(0x7F)>,
			<5 STR_CFG(STR_SPTLB(0x00, 0x02), S2_EN, BL32, PREF_PRED, STLB_PREF, PTLB_NONE)	DIR_READ STR_ID(0x48) STR_MASK(0x7F)>,
			<6 STR_CFG(STR_SPTLB(0x01, 0x03), S2_EN, BL32, PREF_PRED, STLB_PREF, PTLB_NONE)	DIR_READ STR_ID(0x0C) STR_MASK(0x7F)>,
			<7 STR_CFG(STR_SPTLB(0x01, 0x03), S2_EN, BL32, PREF_PRED, STLB_PREF, PTLB_NONE) DIR_READ STR_ID(0x4C) STR_MASK(0x7F)>,
			<8 STR_CFG(STR_SPTLB(0x0B, 0x04), S2_EN, BL2, PREF_PRED, STLB_PREF, PTLB_PREF)	DIR_READ STR_ID(0x09) STR_MASK(0x7F)>,
			<9 STR_CFG(STR_SPTLB(0x0B, 0x04), S2_EN, BL2, PREF_PRED, STLB_PREF, PTLB_PREF)	DIR_READ STR_ID(0x49) STR_MASK(0x7F)>,
			<10 STR_CFG(STR_SPTLB(0x0C, 0x05), S2_EN, BL1, PREF_PRED, STLB_PREF, PTLB_PREF) DIR_READ STR_ID(0x0D) STR_MASK(0x7F)>,
			<11 STR_CFG(STR_SPTLB(0x0C, 0x05), S2_EN, BL1, PREF_PRED, STLB_PREF, PTLB_PREF)	DIR_READ STR_ID(0x4D) STR_MASK(0x7F)>,
			<12 STR_CFG(STR_SPTLB(0x07, 0x06), S2_EN, BL8, PREF_PRED, STLB_PREF, PTLB_NONE)	DIR_READ STR_ID(0x10) STR_MASK(0x7F)>,
			<13 STR_CFG(STR_SPTLB(0x07, 0x06), S2_EN, BL1, PREF_PRED, STLB_PREF, PTLB_NONE) DIR_READ STR_ID(0x50) STR_MASK(0x7F)>,
			<14 STR_CFG(STR_SPTLB(0x0D, 0x07), S2_EN, BL2, PREF_PRED, STLB_PREF, PTLB_PREF) DIR_READ STR_ID(0x11) STR_MASK(0x7F)>,
			<15 STR_CFG(STR_SPTLB(0x0D, 0x07), S2_EN, BL2, PREF_PRED, STLB_PREF, PTLB_PREF) DIR_READ STR_ID(0x51) STR_MASK(0x7F)>,
			<16 STR_CFG(STR_SPTLB(0x02, 0x08), S2_EN, BL32, PREF_PRED, STLB_PREF, PTLB_NONE) DIR_READ STR_ID(0x18) STR_MASK(0x7F)>,
			<17 STR_CFG(STR_SPTLB(0x02, 0x08), S2_EN, BL32, PREF_PRED, STLB_PREF, PTLB_NONE) DIR_READ STR_ID(0x58) STR_MASK(0x7F)>,
			<18 STR_CFG(STR_SPTLB(0x03, 0x09), S2_EN, BL32, PREF_PRED, STLB_PREF, PTLB_NONE) DIR_READ STR_ID(0x1C) STR_MASK(0x7F)>,
			<19 STR_CFG(STR_SPTLB(0x03, 0x09), S2_EN, BL32, PREF_PRED, STLB_PREF, PTLB_NONE) DIR_READ STR_ID(0x5C) STR_MASK(0x7F)>,
			<20 STR_CFG(STR_SPTLB(0x0E, 0x0A), S2_EN, BL2, PREF_PRED, STLB_PREF, PTLB_PREF) DIR_READ STR_ID(0x19) STR_MASK(0x7F)>,
			<21 STR_CFG(STR_SPTLB(0x0E, 0x0A), S2_EN, BL2, PREF_PRED, STLB_PREF, PTLB_PREF) DIR_READ STR_ID(0x59) STR_MASK(0x7F)>,
			<22 STR_CFG(STR_SPTLB(0x0F, 0x0B), S2_EN, BL1, PREF_PRED, STLB_PREF, PTLB_PREF)	DIR_READ STR_ID(0x1D) STR_MASK(0x7F)>,
			<23 STR_CFG(STR_SPTLB(0x0F, 0x0B), S2_EN, BL1, PREF_PRED, STLB_PREF, PTLB_PREF)	DIR_READ STR_ID(0x5D) STR_MASK(0x7F)>,
			<24 STR_CFG(STR_SPTLB(0x14, 0x0C), S2_EN, BL1, PREF_PRED, STLB_PREF, PTLB_PREF)	DIR_READ STR_ID(0x13) STR_MASK(0x7F)>,
			<25 STR_CFG(STR_SPTLB(0x14, 0x0C), S2_EN, BL1, PREF_PRED, STLB_PREF, PTLB_PREF)	DIR_READ STR_ID(0x53) STR_MASK(0x7F)>,
			<26 STR_CFG(STR_SPTLB(0x15, 0x0D), S2_EN, BL1, PREF_PRED, STLB_PREF, PTLB_PREF)	DIR_READ STR_ID(0x0B) STR_MASK(0x7F)>,
			<27 STR_CFG(STR_SPTLB(0x15, 0x0D), S2_EN, BL1, PREF_PRED, STLB_PREF, PTLB_PREF)	DIR_READ STR_ID(0x4B) STR_MASK(0x7F)>,
			<28 STR_CFG(STR_SPTLB(0x16, 0x0E), S2_EN, BL1, PREF_PRED, STLB_PREF, PTLB_PREF)	DIR_WRITE STR_ID(0x00) STR_MASK(0x7F)>,
			<29 STR_CFG(STR_SPTLB(0x16, 0x0E), S2_EN, BL1, PREF_PRED, STLB_PREF, PTLB_PREF)	DIR_WRITE STR_ID(0x40) STR_MASK(0x7F)>,
			<30 STR_CFG(STR_SPTLB(0x17, 0x0F), S2_EN, BL1, PREF_PRED, STLB_PREF, PTLB_PREF)	DIR_WRITE STR_ID(0x10) STR_MASK(0x7F)>,
			<31 STR_CFG(STR_SPTLB(0x17, 0x0F), S2_EN, BL1, PREF_PRED, STLB_PREF, PTLB_PREF)	DIR_WRITE STR_ID(0x50) STR_MASK(0x7F)>,
			<32 STR_CFG(STR_SPTLB(0x18, 0x14), S2_EN, BL1, PREF_PRED, STLB_PREF, PTLB_PREF)	DIR_WRITE STR_ID(0x04) STR_MASK(0x7F)>,
			<33 STR_CFG(STR_SPTLB(0x18, 0x14), S2_EN, BL1, PREF_PRED, STLB_PREF, PTLB_PREF)	DIR_WRITE STR_ID(0x44) STR_MASK(0x7F)>,
			<34 STR_CFG(STR_SPTLB(0x19, 0x15), S2_EN, BL1, PREF_PRED, STLB_PREF, PTLB_PREF)	DIR_WRITE STR_ID(0x14) STR_MASK(0x7F)>,
			<35 STR_CFG(STR_SPTLB(0x19, 0x15), S2_EN, BL1, PREF_PRED, STLB_PREF, PTLB_PREF)	DIR_WRITE STR_ID(0x54) STR_MASK(0x7F)>,
			<36 STR_CFG(STR_SPTLB(0x10, 0x10), S2_EN, BL2, PREF_PRED, STLB_PREF, PTLB_PREF)	DIR_READ STR_ID(0x21) STR_MASK(0x7F)>,
			<37 STR_CFG(STR_SPTLB(0x10, 0x10), S2_EN, BL2, PREF_PRED, STLB_PREF, PTLB_PREF)	DIR_READ STR_ID(0x61) STR_MASK(0x7F)>,
			<38 STR_CFG(STR_SPTLB(0x11, 0x11), S2_EN, BL2, PREF_PRED, STLB_PREF, PTLB_PREF)	DIR_READ STR_ID(0x29) STR_MASK(0x7F)>,
			<39 STR_CFG(STR_SPTLB(0x11, 0x11), S2_EN, BL2, PREF_PRED, STLB_PREF, PTLB_PREF)	DIR_READ STR_ID(0x69) STR_MASK(0x7F)>,
			<40 STR_CFG(STR_SPTLB(0x12, 0x12), S2_EN, BL1, PREF_PRED, STLB_PREF, PTLB_PREF)	DIR_READ STR_ID(0x2D) STR_MASK(0x7F)>,
			<41 STR_CFG(STR_SPTLB(0x12, 0x12), S2_EN, BL1, PREF_PRED, STLB_PREF, PTLB_PREF) DIR_READ STR_ID(0x6D) STR_MASK(0x7F)>,
			<42 STR_CFG(STR_SPTLB(0x13, 0x13), S2_EN, BL2, PREF_PRED, STLB_PREF, PTLB_PREF)	DIR_READ STR_ID(0x31) STR_MASK(0x7F)>,
			<43 STR_CFG(STR_SPTLB(0x13, 0x13), S2_EN, BL2, PREF_PRED, STLB_PREF, PTLB_PREF)	DIR_READ STR_ID(0x71) STR_MASK(0x7F)>;

		pmmu1,default_stream = <STR_CFG(STR_SPTLB(0x08, 0x00), S2_EN, BL16, PREF_PRED, STLB_PREF, PTLB_NONE)>;
		pmmu1,stream_property =
			<1 STR_CFG(STR_SPTLB(0x08, 0x00), S2_EN, BL16, PREF_PRED, STLB_PREF, PTLB_NONE)	DIR_READ STR_ID(0x60) STR_MASK(0x7F)>,
			<2 STR_CFG(STR_SPTLB(0x10, 0x01), S2_EN, BL2, PREF_PRED, STLB_PREF, PTLB_PREF) DIR_READ STR_ID(0x21) STR_MASK(0x7F)>,
			<3 STR_CFG(STR_SPTLB(0x10, 0x01), S2_EN, BL2, PREF_PRED, STLB_PREF, PTLB_PREF) DIR_READ STR_ID(0x61) STR_MASK(0x7F)>,
			<4 STR_CFG(STR_SPTLB(0x04, 0x02), S2_EN, BL32, PREF_PRED, STLB_PREF, PTLB_NONE)	DIR_READ STR_ID(0x28) STR_MASK(0x7F)>,
			<5 STR_CFG(STR_SPTLB(0x04, 0x02), S2_EN, BL32, PREF_PRED, STLB_PREF, PTLB_NONE) DIR_READ STR_ID(0x68) STR_MASK(0x7F)>,
			<6 STR_CFG(STR_SPTLB(0x05, 0x03), S2_EN, BL32, PREF_PRED, STLB_PREF, PTLB_NONE) DIR_READ STR_ID(0x2C) STR_MASK(0x7F)>,
			<7 STR_CFG(STR_SPTLB(0x05, 0x03), S2_EN, BL32, PREF_PRED, STLB_PREF, PTLB_NONE) DIR_READ STR_ID(0x6C) STR_MASK(0x7F)>,
			<8 STR_CFG(STR_SPTLB(0x11, 0x04), S2_EN, BL2, PREF_PRED, STLB_PREF, PTLB_PREF)	DIR_READ STR_ID(0x29) STR_MASK(0x7F)>,
			<9 STR_CFG(STR_SPTLB(0x11, 0x04), S2_EN, BL2, PREF_PRED, STLB_PREF, PTLB_PREF) DIR_READ STR_ID(0x69) STR_MASK(0x7F)>,
			<10 STR_CFG(STR_SPTLB(0x12, 0x05), S2_EN, BL1, PREF_PRED, STLB_PREF, PTLB_PREF)	DIR_READ STR_ID(0x2D) STR_MASK(0x7F)>,
			<11 STR_CFG(STR_SPTLB(0x12, 0x05), S2_EN, BL1, PREF_PRED, STLB_PREF, PTLB_PREF)	DIR_READ STR_ID(0x6D) STR_MASK(0x7F)>,
			<12 STR_CFG(STR_SPTLB(0x09, 0x06), S2_EN, BL16, PREF_PRED, STLB_PREF, PTLB_NONE) DIR_READ STR_ID(0x30) STR_MASK(0x7F)>,
			<13 STR_CFG(STR_SPTLB(0x09, 0x06), S2_EN, BL16, PREF_PRED, STLB_PREF, PTLB_NONE) DIR_READ STR_ID(0x70) STR_MASK(0x7F)>,
			<14 STR_CFG(STR_SPTLB(0x13, 0x07), S2_EN, BL2, PREF_PRED, STLB_PREF, PTLB_PREF) DIR_READ STR_ID(0x31) STR_MASK(0x7F)>,
			<15 STR_CFG(STR_SPTLB(0x13, 0x07), S2_EN, BL2, PREF_PRED, STLB_PREF, PTLB_PREF)	DIR_READ STR_ID(0x71) STR_MASK(0x7F)>,
			<16 STR_CFG(STR_SPTLB(0x1A, 0x08), S2_EN, BL2, PREF_PRED, STLB_PREF, PTLB_NONE) DIR_READ STR_ID(0x2B) STR_MASK(0x7F)>,
			<17 STR_CFG(STR_SPTLB(0x1A, 0x08), S2_EN, BL2, PREF_PRED, STLB_PREF, PTLB_NONE) DIR_READ STR_ID(0x6B) STR_MASK(0x7F)>,
			<18 STR_CFG(STR_SPTLB(0x0A, 0x09), S2_EN, BL2, PREF_PRED, STLB_PREF, PTLB_PREF) DIR_READ STR_ID(0x01) STR_MASK(0x7F)>,
			<19 STR_CFG(STR_SPTLB(0x0A, 0x09), S2_EN, BL2, PREF_PRED, STLB_PREF, PTLB_PREF)	DIR_READ STR_ID(0x41) STR_MASK(0x7F)>,
			<20 STR_CFG(STR_SPTLB(0x0B, 0x0A), S2_EN, BL2, PREF_PRED, STLB_PREF, PTLB_PREF)	DIR_READ STR_ID(0x09) STR_MASK(0x7F)>,
			<21 STR_CFG(STR_SPTLB(0x0B, 0x0A), S2_EN, BL2, PREF_PRED, STLB_PREF, PTLB_PREF) DIR_READ STR_ID(0x49) STR_MASK(0x7F)>,
			<22 STR_CFG(STR_SPTLB(0x0C, 0x0B), S2_EN, BL2, PREF_PRED, STLB_PREF, PTLB_PREF)	DIR_READ STR_ID(0x0D) STR_MASK(0x7F)>,
			<23 STR_CFG(STR_SPTLB(0x0C, 0x0B), S2_EN, BL2, PREF_PRED, STLB_PREF, PTLB_PREF)	DIR_READ STR_ID(0x4D) STR_MASK(0x7F)>,
			<24 STR_CFG(STR_SPTLB(0x0D, 0x0C), S2_EN, BL2, PREF_PRED, STLB_PREF, PTLB_PREF)	DIR_READ STR_ID(0x11) STR_MASK(0x7F)>,
			<25 STR_CFG(STR_SPTLB(0x0D, 0x0C), S2_EN, BL2, PREF_PRED, STLB_PREF, PTLB_PREF)	DIR_READ STR_ID(0x51) STR_MASK(0x7F)>,
			<26 STR_CFG(STR_SPTLB(0x0E, 0x0D), S2_EN, BL2, PREF_PRED, STLB_PREF, PTLB_PREF)	DIR_READ STR_ID(0x19) STR_MASK(0x7F)>,
			<27 STR_CFG(STR_SPTLB(0x0E, 0x0D), S2_EN, BL2, PREF_PRED, STLB_PREF, PTLB_PREF)	DIR_READ STR_ID(0x59) STR_MASK(0x7F)>,
			<28 STR_CFG(STR_SPTLB(0x0F, 0x0E), S2_EN, BL2, PREF_PRED, STLB_PREF, PTLB_PREF) DIR_READ STR_ID(0x1D) STR_MASK(0x7F)>,
			<29 STR_CFG(STR_SPTLB(0x0F, 0x0E), S2_EN, BL2, PREF_PRED, STLB_PREF, PTLB_PREF) DIR_READ STR_ID(0x5D) STR_MASK(0x7F)>;
	};

	sysmmu_dpuf1: sysmmu@19C40000 {
		compatible = "samsung,sysmmu-v9";
		reg = <0x0 0x19C40000 0x10000>;

		interrupts = <0 IRQ_SYSMMU_S0_DPUF1_S1_NS_DPUF1 IRQ_TYPE_LEVEL_HIGH>,
			     <0 IRQ_SYSMMU_S0_DPUF1_S1_S_DPUF1 IRQ_TYPE_LEVEL_HIGH>;

		qos = <15>;

		sysmmu,secure-irq;
		sysmmu,secure_base = <0x19C50000>;
/*              power-domains = <&pd_dpu>;
 */
		port-name = "DPU F1";
		#iommu-cells = <0>;
		pmmu0,default_stream = <STR_CFG(STR_SPTLB(0x06, 0x00), S2_EN, BL16, PREF_PRED, STLB_PREF, PTLB_NONE)>;
		pmmu0,stream_property =
			<1 STR_CFG(STR_SPTLB(0x06, 0x00), S2_EN, BL16, PREF_PRED, STLB_PREF, PTLB_NONE)	DIR_READ STR_ID(0x40) STR_MASK(0x7F)>,
			<2 STR_CFG(STR_SPTLB(0x0A, 0x01), S2_EN, BL2, PREF_PRED, STLB_PREF, PTLB_PREF) DIR_READ STR_ID(0x01) STR_MASK(0x7F)>,
			<3 STR_CFG(STR_SPTLB(0x0A, 0x01), S2_EN, BL2, PREF_PRED, STLB_PREF, PTLB_PREF) DIR_READ STR_ID(0x41) STR_MASK(0x7F)>,
			<4 STR_CFG(STR_SPTLB(0x00, 0x02), S2_EN, BL32, PREF_PRED, STLB_PREF, PTLB_NONE) DIR_READ STR_ID(0x08) STR_MASK(0x7F)>,
			<5 STR_CFG(STR_SPTLB(0x00, 0x02), S2_EN, BL32, PREF_PRED, STLB_PREF, PTLB_NONE)	DIR_READ STR_ID(0x48) STR_MASK(0x7F)>,
			<6 STR_CFG(STR_SPTLB(0x01, 0x03), S2_EN, BL32, PREF_PRED, STLB_PREF, PTLB_NONE)	DIR_READ STR_ID(0x0C) STR_MASK(0x7F)>,
			<7 STR_CFG(STR_SPTLB(0x01, 0x03), S2_EN, BL32, PREF_PRED, STLB_PREF, PTLB_NONE)	DIR_READ STR_ID(0x4C) STR_MASK(0x7F)>,
			<8 STR_CFG(STR_SPTLB(0x0B, 0x04), S2_EN, BL2, PREF_PRED, STLB_PREF, PTLB_PREF) DIR_READ STR_ID(0x09) STR_MASK(0x7F)>,
			<9 STR_CFG(STR_SPTLB(0x0B, 0x04), S2_EN, BL2, PREF_PRED, STLB_PREF, PTLB_PREF) DIR_READ STR_ID(0x49) STR_MASK(0x7F)>,
			<10 STR_CFG(STR_SPTLB(0x0C, 0x05), S2_EN, BL1, PREF_PRED, STLB_PREF, PTLB_PREF)	DIR_READ STR_ID(0x0D) STR_MASK(0x7F)>,
			<11 STR_CFG(STR_SPTLB(0x0C, 0x05), S2_EN, BL1, PREF_PRED, STLB_PREF, PTLB_PREF)	DIR_READ STR_ID(0x4D) STR_MASK(0x7F)>,
			<12 STR_CFG(STR_SPTLB(0x07, 0x06), S2_EN, BL8, PREF_PRED, STLB_PREF, PTLB_NONE)	DIR_READ STR_ID(0x10) STR_MASK(0x7F)>,
			<13 STR_CFG(STR_SPTLB(0x07, 0x06), S2_EN, BL1, PREF_PRED, STLB_PREF, PTLB_NONE)	DIR_READ STR_ID(0x50) STR_MASK(0x7F)>,
			<14 STR_CFG(STR_SPTLB(0x0D, 0x07), S2_EN, BL2, PREF_PRED, STLB_PREF, PTLB_PREF)	DIR_READ STR_ID(0x11) STR_MASK(0x7F)>,
			<15 STR_CFG(STR_SPTLB(0x0D, 0x07), S2_EN, BL2, PREF_PRED, STLB_PREF, PTLB_PREF) DIR_READ STR_ID(0x51) STR_MASK(0x7F)>,
			<16 STR_CFG(STR_SPTLB(0x02, 0x08), S2_EN, BL32, PREF_PRED, STLB_PREF, PTLB_NONE) DIR_READ STR_ID(0x18) STR_MASK(0x7F)>,
			<17 STR_CFG(STR_SPTLB(0x02, 0x08), S2_EN, BL32, PREF_PRED, STLB_PREF, PTLB_NONE) DIR_READ STR_ID(0x58) STR_MASK(0x7F)>,
			<18 STR_CFG(STR_SPTLB(0x03, 0x09), S2_EN, BL32, PREF_PRED, STLB_PREF, PTLB_NONE) DIR_READ STR_ID(0x1C) STR_MASK(0x7F)>,
			<19 STR_CFG(STR_SPTLB(0x03, 0x09), S2_EN, BL32, PREF_PRED, STLB_PREF, PTLB_NONE) DIR_READ STR_ID(0x5C) STR_MASK(0x7F)>,
			<20 STR_CFG(STR_SPTLB(0x0E, 0x0A), S2_EN, BL2, PREF_PRED, STLB_PREF, PTLB_PREF) DIR_READ STR_ID(0x19) STR_MASK(0x7F)>,
			<21 STR_CFG(STR_SPTLB(0x0E, 0x0A), S2_EN, BL2, PREF_PRED, STLB_PREF, PTLB_PREF)	DIR_READ STR_ID(0x59) STR_MASK(0x7F)>,
			<22 STR_CFG(STR_SPTLB(0x0F, 0x0B), S2_EN, BL1, PREF_PRED, STLB_PREF, PTLB_PREF)	DIR_READ STR_ID(0x1D) STR_MASK(0x7F)>,
			<23 STR_CFG(STR_SPTLB(0x0F, 0x0B), S2_EN, BL1, PREF_PRED, STLB_PREF, PTLB_PREF)	DIR_READ STR_ID(0x5D) STR_MASK(0x7F)>,
			<24 STR_CFG(STR_SPTLB(0x14, 0x0C), S2_EN, BL1, PREF_PRED, STLB_PREF, PTLB_PREF)	DIR_READ STR_ID(0x13) STR_MASK(0x7F)>,
			<25 STR_CFG(STR_SPTLB(0x14, 0x0C), S2_EN, BL1, PREF_PRED, STLB_PREF, PTLB_PREF)	DIR_READ STR_ID(0x53) STR_MASK(0x7F)>,
			<26 STR_CFG(STR_SPTLB(0x15, 0x0D), S2_EN, BL1, PREF_PRED, STLB_PREF, PTLB_PREF)	DIR_READ STR_ID(0x0B) STR_MASK(0x7F)>,
			<27 STR_CFG(STR_SPTLB(0x15, 0x0D), S2_EN, BL1, PREF_PRED, STLB_PREF, PTLB_PREF)	DIR_READ STR_ID(0x4B) STR_MASK(0x7F)>,
			<28 STR_CFG(STR_SPTLB(0x16, 0x0E), S2_EN, BL1, PREF_PRED, STLB_PREF, PTLB_PREF)	DIR_WRITE STR_ID(0x00) STR_MASK(0x7F)>,
			<29 STR_CFG(STR_SPTLB(0x16, 0x0E), S2_EN, BL1, PREF_PRED, STLB_PREF, PTLB_PREF)	DIR_WRITE STR_ID(0x40) STR_MASK(0x7F)>,
			<30 STR_CFG(STR_SPTLB(0x17, 0x0F), S2_EN, BL1, PREF_PRED, STLB_PREF, PTLB_PREF)	DIR_WRITE STR_ID(0x10) STR_MASK(0x7F)>,
			<31 STR_CFG(STR_SPTLB(0x17, 0x0F), S2_EN, BL1, PREF_PRED, STLB_PREF, PTLB_PREF)	DIR_WRITE STR_ID(0x50) STR_MASK(0x7F)>,
			<32 STR_CFG(STR_SPTLB(0x18, 0x14), S2_EN, BL1, PREF_PRED, STLB_PREF, PTLB_PREF) DIR_WRITE STR_ID(0x04) STR_MASK(0x7F)>,
			<33 STR_CFG(STR_SPTLB(0x18, 0x14), S2_EN, BL1, PREF_PRED, STLB_PREF, PTLB_PREF) DIR_WRITE STR_ID(0x44) STR_MASK(0x7F)>,
			<34 STR_CFG(STR_SPTLB(0x19, 0x15), S2_EN, BL1, PREF_PRED, STLB_PREF, PTLB_PREF)	DIR_WRITE STR_ID(0x14) STR_MASK(0x7F)>,
			<35 STR_CFG(STR_SPTLB(0x19, 0x15), S2_EN, BL1, PREF_PRED, STLB_PREF, PTLB_PREF)	DIR_WRITE STR_ID(0x54) STR_MASK(0x7F)>,
			<36 STR_CFG(STR_SPTLB(0x10, 0x10), S2_EN, BL2, PREF_PRED, STLB_PREF, PTLB_PREF)	DIR_READ STR_ID(0x21) STR_MASK(0x7F)>,
			<37 STR_CFG(STR_SPTLB(0x10, 0x10), S2_EN, BL2, PREF_PRED, STLB_PREF, PTLB_PREF)	DIR_READ STR_ID(0x61) STR_MASK(0x7F)>,
			<38 STR_CFG(STR_SPTLB(0x11, 0x11), S2_EN, BL2, PREF_PRED, STLB_PREF, PTLB_PREF)	DIR_READ STR_ID(0x29) STR_MASK(0x7F)>,
			<39 STR_CFG(STR_SPTLB(0x11, 0x11), S2_EN, BL2, PREF_PRED, STLB_PREF, PTLB_PREF)	DIR_READ STR_ID(0x69) STR_MASK(0x7F)>,
			<40 STR_CFG(STR_SPTLB(0x12, 0x12), S2_EN, BL1, PREF_PRED, STLB_PREF, PTLB_PREF)	DIR_READ STR_ID(0x2D) STR_MASK(0x7F)>,
			<41 STR_CFG(STR_SPTLB(0x12, 0x12), S2_EN, BL1, PREF_PRED, STLB_PREF, PTLB_PREF)	DIR_READ STR_ID(0x6D) STR_MASK(0x7F)>,
			<42 STR_CFG(STR_SPTLB(0x13, 0x13), S2_EN, BL2, PREF_PRED, STLB_PREF, PTLB_PREF)	DIR_READ STR_ID(0x31) STR_MASK(0x7F)>,
			<43 STR_CFG(STR_SPTLB(0x13, 0x13), S2_EN, BL2, PREF_PRED, STLB_PREF, PTLB_PREF)	DIR_READ STR_ID(0x71) STR_MASK(0x7F)>;
		pmmu1,default_stream = <STR_CFG(STR_SPTLB(0x08, 0x00), S2_EN, BL16, PREF_PRED, STLB_PREF, PTLB_NONE)>;
		pmmu1,stream_property =
			<1 STR_CFG(STR_SPTLB(0x08, 0x00), S2_EN, BL16, PREF_PRED, STLB_PREF, PTLB_NONE)	DIR_READ STR_ID(0x60) STR_MASK(0x7F)>,
			<2 STR_CFG(STR_SPTLB(0x10, 0x01), S2_EN, BL2, PREF_PRED, STLB_PREF, PTLB_PREF) DIR_READ STR_ID(0x21) STR_MASK(0x7F)>,
			<3 STR_CFG(STR_SPTLB(0x10, 0x01), S2_EN, BL2, PREF_PRED, STLB_PREF, PTLB_PREF) DIR_READ STR_ID(0x61) STR_MASK(0x7F)>,
			<4 STR_CFG(STR_SPTLB(0x04, 0x02), S2_EN, BL32, PREF_PRED, STLB_PREF, PTLB_NONE) DIR_READ STR_ID(0x28) STR_MASK(0x7F)>,
			<5 STR_CFG(STR_SPTLB(0x04, 0x02), S2_EN, BL32, PREF_PRED, STLB_PREF, PTLB_NONE) DIR_READ STR_ID(0x68) STR_MASK(0x7F)>,
			<6 STR_CFG(STR_SPTLB(0x05, 0x03), S2_EN, BL32, PREF_PRED, STLB_PREF, PTLB_NONE)	DIR_READ STR_ID(0x2C) STR_MASK(0x7F)>,
			<7 STR_CFG(STR_SPTLB(0x05, 0x03), S2_EN, BL32, PREF_PRED, STLB_PREF, PTLB_NONE)	DIR_READ STR_ID(0x6C) STR_MASK(0x7F)>,
			<8 STR_CFG(STR_SPTLB(0x11, 0x04), S2_EN, BL2, PREF_PRED, STLB_PREF, PTLB_PREF)	DIR_READ STR_ID(0x29) STR_MASK(0x7F)>,
			<9 STR_CFG(STR_SPTLB(0x11, 0x04), S2_EN, BL2, PREF_PRED, STLB_PREF, PTLB_PREF)	DIR_READ STR_ID(0x69) STR_MASK(0x7F)>,
			<10 STR_CFG(STR_SPTLB(0x12, 0x05), S2_EN, BL1, PREF_PRED, STLB_PREF, PTLB_PREF)	DIR_READ STR_ID(0x2D) STR_MASK(0x7F)>,
			<11 STR_CFG(STR_SPTLB(0x12, 0x05), S2_EN, BL1, PREF_PRED, STLB_PREF, PTLB_PREF)	DIR_READ STR_ID(0x6D) STR_MASK(0x7F)>,
			<12 STR_CFG(STR_SPTLB(0x09, 0x06), S2_EN, BL16, PREF_PRED, STLB_PREF, PTLB_NONE) DIR_READ STR_ID(0x30) STR_MASK(0x7F)>,
			<13 STR_CFG(STR_SPTLB(0x09, 0x06), S2_EN, BL16, PREF_PRED, STLB_PREF, PTLB_NONE) DIR_READ STR_ID(0x70) STR_MASK(0x7F)>,
			<14 STR_CFG(STR_SPTLB(0x13, 0x07), S2_EN, BL2, PREF_PRED, STLB_PREF, PTLB_PREF) DIR_READ STR_ID(0x31) STR_MASK(0x7F)>,
			<15 STR_CFG(STR_SPTLB(0x13, 0x07), S2_EN, BL2, PREF_PRED, STLB_PREF, PTLB_PREF) DIR_READ STR_ID(0x71) STR_MASK(0x7F)>,
			<16 STR_CFG(STR_SPTLB(0x1A, 0x08), S2_EN, BL2, PREF_PRED, STLB_PREF, PTLB_NONE)	DIR_READ STR_ID(0x2B) STR_MASK(0x7F)>,
			<17 STR_CFG(STR_SPTLB(0x1A, 0x08), S2_EN, BL2, PREF_PRED, STLB_PREF, PTLB_NONE)	DIR_READ STR_ID(0x6B) STR_MASK(0x7F)>,
			<18 STR_CFG(STR_SPTLB(0x0A, 0x09), S2_EN, BL2, PREF_PRED, STLB_PREF, PTLB_PREF)	DIR_READ STR_ID(0x01) STR_MASK(0x7F)>,
			<19 STR_CFG(STR_SPTLB(0x0A, 0x09), S2_EN, BL2, PREF_PRED, STLB_PREF, PTLB_PREF)	DIR_READ STR_ID(0x41) STR_MASK(0x7F)>,
			<20 STR_CFG(STR_SPTLB(0x0B, 0x0A), S2_EN, BL2, PREF_PRED, STLB_PREF, PTLB_PREF)	DIR_READ STR_ID(0x09) STR_MASK(0x7F)>,
			<21 STR_CFG(STR_SPTLB(0x0B, 0x0A), S2_EN, BL2, PREF_PRED, STLB_PREF, PTLB_PREF)	DIR_READ STR_ID(0x49) STR_MASK(0x7F)>,
			<22 STR_CFG(STR_SPTLB(0x0C, 0x0B), S2_EN, BL2, PREF_PRED, STLB_PREF, PTLB_PREF)	DIR_READ STR_ID(0x0D) STR_MASK(0x7F)>,
			<23 STR_CFG(STR_SPTLB(0x0C, 0x0B), S2_EN, BL2, PREF_PRED, STLB_PREF, PTLB_PREF)	DIR_READ STR_ID(0x4D) STR_MASK(0x7F)>,
			<24 STR_CFG(STR_SPTLB(0x0D, 0x0C), S2_EN, BL2, PREF_PRED, STLB_PREF, PTLB_PREF) DIR_READ STR_ID(0x11) STR_MASK(0x7F)>,
			<25 STR_CFG(STR_SPTLB(0x0D, 0x0C), S2_EN, BL2, PREF_PRED, STLB_PREF, PTLB_PREF)	DIR_READ STR_ID(0x51) STR_MASK(0x7F)>,
			<26 STR_CFG(STR_SPTLB(0x0E, 0x0D), S2_EN, BL2, PREF_PRED, STLB_PREF, PTLB_PREF)	DIR_READ STR_ID(0x19) STR_MASK(0x7F)>,
			<27 STR_CFG(STR_SPTLB(0x0E, 0x0D), S2_EN, BL2, PREF_PRED, STLB_PREF, PTLB_PREF)	DIR_READ STR_ID(0x59) STR_MASK(0x7F)>,
			<28 STR_CFG(STR_SPTLB(0x0F, 0x0E), S2_EN, BL2, PREF_PRED, STLB_PREF, PTLB_PREF)	DIR_READ STR_ID(0x1D) STR_MASK(0x7F)>,
			<29 STR_CFG(STR_SPTLB(0x0F, 0x0E), S2_EN, BL2, PREF_PRED, STLB_PREF, PTLB_PREF)	DIR_READ STR_ID(0x5D) STR_MASK(0x7F)>;
	};

	sysmmu_ispfe_s0: sysmmu@1C110000 {
		compatible = "samsung,sysmmu-v9";
		reg = <0x0 0x1C110000 0x10000>;

		interrupts = <0 IRQ_SYSMMU_S0_ISPFE_S1_NONSECURE_ISPFE IRQ_TYPE_LEVEL_HIGH>,
			     <0 IRQ_SYSMMU_S0_ISPFE_S1_SECURE_ISPFE IRQ_TYPE_LEVEL_HIGH>;

		qos = <15>;

		sysmmu,secure-irq;
		sysmmu,secure_base = <0x1C120000>;
/*		power-domains = <&pd_ispfe>;
 */
		port-name = "ISPFE S0";
		#iommu-cells = <0>;
		pmmu0,default_stream = <STR_CFG(STR_SPTLB(0x06, 0x03), S2_EN, BL1, PREF_ASC, STLB_PREF, PTLB_PREF)>;
		pmmu0,stream_property =
			<1 STR_CFG(STR_SPTLB(0x01, 0x0), S2_EN, BL1, PREF_ASC, STLB_PREF, PTLB_PREF) DIR_WRITE STR_ID(0x20) STR_MASK(0x78)>,
			<2 STR_CFG(STR_SPTLB(0x02, 0x01), S2_EN, BL1, PREF_ASC, STLB_PREF, PTLB_PREF) DIR_WRITE STR_ID(0x28) STR_MASK(0x78)>,
			<3 STR_CFG(STR_SPTLB(0x03, 0x02), S2_EN, BL1, PREF_ASC, STLB_PREF, PTLB_PREF) DIR_WRITE STR_ID(0x30) STR_MASK(0x78)>,
			<4 STR_CFG(STR_SPTLB(0x05, 0x04), S2_EN, BL1, PREF_ASC, STLB_PREF, PTLB_PREF) DIR_WRITE STR_ID(0x40) STR_MASK(0x60)>,
			<5 STR_CFG(STR_SPTLB(0x09, 0x05), S2_EN, BL1, PREF_ASC, STLB_PREF, PTLB_PREF) DIR_WRITE STR_ID(0x40) STR_MASK(0x60)>,
			<6 STR_CFG(STR_SPTLB(0x08, 0x06), S2_EN, BL1, PREF_ASC, STLB_PREF, PTLB_PREF) DIR_WRITE STR_ID(0x40) STR_MASK(0x60)>,
			<7 STR_CFG(STR_SPTLB(0x04, 0x08), S2_EN, BL1, PREF_ASC, STLB_PREF, PTLB_PREF) DIR_READ STR_ID(0x40) STR_MASK(0x60)>,
			<8 STR_CFG(STR_SPTLB(0x00, 0x07), S2_EN, BL1, PREF_ASC, STLB_PREF, PTLB_PREF) DIR_READ STR_ID(0x20) STR_MASK(0x60)>;
		pmmu1,default_stream = <0x07030107>;
		pmmu1,stream_property =
			<1 STR_CFG(STR_SPTLB(0x01, 0x00), S2_EN, BL1, PREF_ASC, STLB_PREF, PTLB_PREF) DIR_WRITE STR_ID(0x28) STR_MASK(0x78)>,
			<2 STR_CFG(STR_SPTLB(0x02, 0x01), S2_EN, BL1, PREF_ASC, STLB_PREF, PTLB_PREF) DIR_WRITE STR_ID(0x30) STR_MASK(0x78)>,
			<3 STR_CFG(STR_SPTLB(0x03, 0x02), S2_EN, BL1, PREF_ASC, STLB_PREF, PTLB_PREF) DIR_WRITE STR_ID(0x38) STR_MASK(0x78)>,
			<4 STR_CFG(STR_SPTLB(0x05, 0x04), S2_EN, BL1, PREF_ASC, STLB_PREF, PTLB_PREF) DIR_WRITE STR_ID(0x40) STR_MASK(0x78)>,
			<5 STR_CFG(STR_SPTLB(0x09, 0x05), S2_EN, BL1, PREF_ASC, STLB_PREF, PTLB_PREF) DIR_WRITE STR_ID(0x48) STR_MASK(0x78)>,
			<6 STR_CFG(STR_SPTLB(0x08, 0x06), S2_EN, BL1, PREF_ASC, STLB_PREF, PTLB_PREF) DIR_WRITE STR_ID(0x50) STR_MASK(0x78)>;
	};

	sysmmu_ispfe_s1: sysmmu@1C150000 {
		compatible = "samsung,sysmmu-v9";
		reg = <0x0 0x1C150000 0x10000>;

		interrupts = <0 IRQ_SYSMMU_S1_ISPFE_S1_NONSECURE_ISPFE IRQ_TYPE_LEVEL_HIGH>,
			     <0 IRQ_SYSMMU_S1_ISPFE_S1_SECURE_ISPFE IRQ_TYPE_LEVEL_HIGH>;

		qos = <15>;

		sysmmu,secure-irq;
		sysmmu,secure_base = <0x1C160000>;
/*		power-domains = <&pd_ispfe>;
 */
		port-name = "ISPFE S1";
		#iommu-cells = <0>;
		pmmu0,default_stream = <STR_CFG(STR_SPTLB(0x00, 0x00), S2_EN, BL1, PREF_ASC, STLB_PREF, PTLB_PREF)>;
	};

	sysmmu_ispfe_s2: sysmmu@1C190000 {
		compatible = "samsung,sysmmu-v9";
		reg = <0x0 0x1C190000 0x10000>;

		interrupts = <0 IRQ_SYSMMU_S2_ISPFE_S1_NONSECURE_ISPFE IRQ_TYPE_LEVEL_HIGH>,
			     <0 IRQ_SYSMMU_S2_ISPFE_S1_SECURE_ISPFE IRQ_TYPE_LEVEL_HIGH>;

		qos = <15>;

		sysmmu,secure-irq;
		sysmmu,secure_base = <0x1C1A0000>;
/*		power-domains = <&pd_ispfe>;
 */
		port-name = "ISPFE S2";
		#iommu-cells = <0>;
		pmmu0,default_stream = <STR_CFG(STR_SPTLB(0x00, 0x00), S2_EN, BL1, PREF_ASC, STLB_PREF, PTLB_PREF)>;
		pmmu0,stream_property =
			<1 STR_CFG(STR_SPTLB(0x00, 0x00), S2_EN, BL1, PREF_ASC, STLB_PREF, PTLB_PREF) DIR_WRITE STR_ID(0x60) STR_MASK(0x60)>,
			<2 STR_CFG(STR_SPTLB(0x00, 0x00), S2_EN, BL1, PREF_ASC, STLB_PREF, PTLB_PREF) DIR_WRITE STR_ID(0x60) STR_MASK(0x60)>,
			<3 STR_CFG(STR_SPTLB(0x03, 0x03), S2_EN, BL1, PREF_ASC, STLB_PREF, PTLB_PREF) DIR_WRITE STR_ID(0x00) STR_MASK(0x60)>,
			<4 STR_CFG(STR_SPTLB(0x01, 0x01), S2_EN, BL1, PREF_ASC, STLB_PREF, PTLB_PREF) DIR_WRITE STR_ID(0x20) STR_MASK(0x60)>,
			<5 STR_CFG(STR_SPTLB(0x02, 0x02), S2_EN, BL1, PREF_ASC, STLB_PREF, PTLB_PREF) DIR_WRITE STR_ID(0x60) STR_MASK(0x60)>;
	};

	sysmmu_gse: sysmmu@1D870000 {
		compatible = "samsung,sysmmu-v9";
		reg = <0x0 0x1D870000 0x10000>;

		interrupts = <0 IRQ_SYSMMU_S0_GSE_S1_NS_GSE IRQ_TYPE_LEVEL_HIGH>,
			     <0 IRQ_SYSMMU_S0_GSE_S1_S_GSE IRQ_TYPE_LEVEL_HIGH>;

		qos = <15>;

		sysmmu,secure-irq;
		sysmmu,secure_base = <0x1D880000>;
/*		power-domains = <&pd_gse>;
 */
		port-name = "GSE";
		#iommu-cells = <0>;
		pmmu0,default_stream = <STR_CFG(STR_SPTLB(0x09, 0x00), S2_EN, BL1, PREF_ASC, STLB_PREF, PTLB_PREF)>;
		pmmu0,stream_property =
			<1 STR_CFG(STR_SPTLB(0x09, 0x00), S2_EN, BL1, PREF_ASC, STLB_PREF, PTLB_PREF) DIR_WRITE STR_ID(0x04) STR_MASK(0x3F)>,
			<2 STR_CFG(STR_SPTLB(0x00, 0x00), S2_EN, BL1, PREF_ASC, STLB_PREF, PTLB_PREF) DIR_WRITE STR_ID(0x08) STR_MASK(0x3F)>,
			<3 STR_CFG(STR_SPTLB(0x00, 0x00), S2_EN, BL1, PREF_ASC, STLB_PREF, PTLB_PREF) DIR_WRITE STR_ID(0x0C) STR_MASK(0x3F)>,
			<4 STR_CFG(STR_SPTLB(0x03, 0x00), S2_EN, BL1, PREF_ASC, STLB_PREF, PTLB_PREF) DIR_WRITE STR_ID(0x10) STR_MASK(0x3F)>,
			<5 STR_CFG(STR_SPTLB(0x03, 0x00), S2_EN, BL1, PREF_ASC, STLB_PREF, PTLB_PREF) DIR_WRITE STR_ID(0x14) STR_MASK(0x3F)>,
			<6 STR_CFG(STR_SPTLB(0x06, 0x00), S2_EN, BL1, PREF_ASC, STLB_PREF, PTLB_PREF) DIR_WRITE STR_ID(0x18) STR_MASK(0x3F)>,
			<7 STR_CFG(STR_SPTLB(0x06, 0x00), S2_EN, BL1, PREF_ASC, STLB_PREF, PTLB_PREF) DIR_WRITE STR_ID(0x1C) STR_MASK(0x3F)>,
			<8 STR_CFG(STR_SPTLB(0x01, 0x00), S2_EN, BL1, PREF_ASC, STLB_PREF, PTLB_PREF) DIR_WRITE STR_ID(0x20) STR_MASK(0x3F)>,
			<9 STR_CFG(STR_SPTLB(0x01, 0x00), S2_EN, BL1, PREF_ASC, STLB_PREF, PTLB_PREF) DIR_WRITE STR_ID(0x24) STR_MASK(0x3F)>,
			<10 STR_CFG(STR_SPTLB(0x04, 0x00), S2_EN, BL1, PREF_ASC, STLB_PREF, PTLB_PREF) DIR_READ STR_ID(0x00) STR_MASK(0x3F)>,
			<11 STR_CFG(STR_SPTLB(0x04, 0x00), S2_EN, BL1, PREF_ASC, STLB_PREF, PTLB_PREF) DIR_READ STR_ID(0x04) STR_MASK(0x3F)>,
			<12 STR_CFG(STR_SPTLB(0x07, 0x00), S2_EN, BL1, PREF_ASC, STLB_PREF, PTLB_PREF) DIR_READ STR_ID(0x08) STR_MASK(0x3F)>,
			<13 STR_CFG(STR_SPTLB(0x07, 0x00), S2_EN, BL1, PREF_ASC, STLB_PREF, PTLB_PREF) DIR_READ STR_ID(0x0C) STR_MASK(0x3F)>,
			<14 STR_CFG(STR_SPTLB(0x02, 0x00), S2_EN, BL1, PREF_ASC, STLB_PREF, PTLB_PREF) DIR_READ STR_ID(0x10) STR_MASK(0x3F)>,
			<15 STR_CFG(STR_SPTLB(0x02, 0x00), S2_EN, BL1, PREF_ASC, STLB_PREF, PTLB_PREF) DIR_READ STR_ID(0x14) STR_MASK(0x3F)>,
			<16 STR_CFG(STR_SPTLB(0x05, 0x00), S2_EN, BL1, PREF_ASC, STLB_PREF, PTLB_PREF) DIR_READ STR_ID(0x18) STR_MASK(0x3F)>,
			<17 STR_CFG(STR_SPTLB(0x05, 0x00), S2_EN, BL1, PREF_ASC, STLB_PREF, PTLB_PREF) DIR_READ STR_ID(0x1C) STR_MASK(0x3F)>,
			<18 STR_CFG(STR_SPTLB(0x08, 0x00), S2_EN, BL1, PREF_ASC, STLB_PREF, PTLB_PREF) DIR_READ STR_ID(0x20) STR_MASK(0x3F)>,
			<19 STR_CFG(STR_SPTLB(0x08, 0x00), S2_EN, BL1, PREF_ASC, STLB_PREF, PTLB_PREF) DIR_READ STR_ID(0x24) STR_MASK(0x3F)>,
			<20 STR_CFG(STR_SPTLB(0x00, 0x00), S2_EN, BL1, PREF_ASC, STLB_PREF, PTLB_PREF) DIR_WRITE STR_ID(0x01) STR_MASK(0x3F)>,
			<21 STR_CFG(STR_SPTLB(0x00, 0x00), S2_EN, BL1, PREF_ASC, STLB_PREF, PTLB_PREF) DIR_WRITE STR_ID(0x05) STR_MASK(0x3F)>,
			<22 STR_CFG(STR_SPTLB(0x00, 0x00), S2_EN, BL1, PREF_ASC, STLB_PREF, PTLB_PREF) DIR_WRITE STR_ID(0x09) STR_MASK(0x3F)>,
			<23 STR_CFG(STR_SPTLB(0x00, 0x00), S2_EN, BL1, PREF_ASC, STLB_PREF, PTLB_PREF) DIR_WRITE STR_ID(0x0D) STR_MASK(0x3F)>,
			<24 STR_CFG(STR_SPTLB(0x00, 0x00), S2_EN, BL1, PREF_ASC, STLB_PREF, PTLB_PREF) DIR_WRITE STR_ID(0x11) STR_MASK(0x3F)>,
			<25 STR_CFG(STR_SPTLB(0x00, 0x00), S2_EN, BL1, PREF_ASC, STLB_PREF, PTLB_PREF) DIR_WRITE STR_ID(0x15) STR_MASK(0x3F)>,
			<26 STR_CFG(STR_SPTLB(0x00, 0x00), S2_EN, BL1, PREF_ASC, STLB_PREF, PTLB_PREF) DIR_WRITE STR_ID(0x19) STR_MASK(0x3F)>,
			<27 STR_CFG(STR_SPTLB(0x00, 0x00), S2_EN, BL1, PREF_ASC, STLB_PREF, PTLB_PREF) DIR_WRITE STR_ID(0x1D) STR_MASK(0x3F)>,
			<28 STR_CFG(STR_SPTLB(0x00, 0x00), S2_EN, BL1, PREF_ASC, STLB_PREF, PTLB_PREF) DIR_WRITE STR_ID(0x21) STR_MASK(0x3F)>,
			<29 STR_CFG(STR_SPTLB(0x00, 0x00), S2_EN, BL1, PREF_ASC, STLB_PREF, PTLB_PREF) DIR_WRITE STR_ID(0x25) STR_MASK(0x3F)>,
			<30 STR_CFG(STR_SPTLB(0x00, 0x00), S2_EN, BL1, PREF_ASC, STLB_PREF, PTLB_PREF) DIR_WRITE STR_ID(0x2D) STR_MASK(0x3F)>,
			<31 STR_CFG(STR_SPTLB(0x00, 0x00), S2_EN, BL1, PREF_ASC, STLB_PREF, PTLB_PREF) DIR_WRITE STR_ID(0x02) STR_MASK(0x07)>,
			<32 STR_CFG(STR_SPTLB(0x00, 0x00), S2_EN, BL1, PREF_ASC, STLB_PREF, PTLB_PREF) DIR_WRITE STR_ID(0x06) STR_MASK(0x07)>;
	};

};
